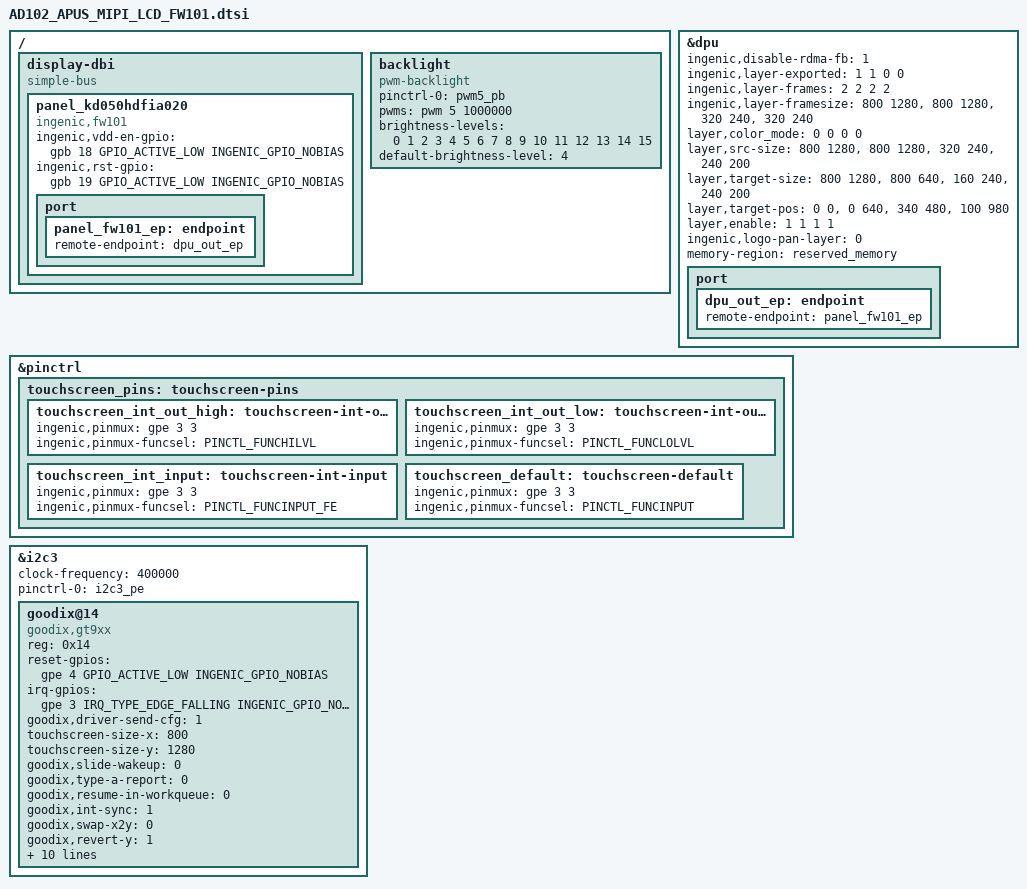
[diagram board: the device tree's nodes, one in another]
&dpu {
	status = "okay";
	ingenic,disable-rdma-fb = <1>;
	/*Defines the init state of composer fb export infomations.*/
	ingenic,layer-exported = <1 1 0 0>;
	ingenic,layer-frames   = <2 2 2 2>;
	ingenic,layer-framesize = <800 1280>, <800 1280>, <320 240>, <320 240>;   /*Max framesize for each layer.*/
	layer,color_mode        = <0 0 0 0>;                                    /*src fmt,*/
	layer,src-size          = <800 1280>, <800 1280>, <320 240>, <240 200>; /*Layer src size should smaller than framesize*/
	layer,target-size       = <800 1280>, <800 640>, <160 240>, <240 200>;  /*Target Size should smaller than src_size.*/
	layer,target-pos        = <0 0>, <0 640>, <340 480>, <100 980>; /*target pos , the start point of the target panel.*/
	layer,enable            = <1 1 1 1>;                                    /*layer enabled or disabled.*/
	ingenic,logo-pan-layer  = <0>;                                          /*on which layer should init logo pan on.*/
	memory-region=<&reserved_memory>;
	port {
		dpu_out_ep: endpoint {
		    remote-endpoint = <&panel_fw101_ep>;
		};
	};
};

/ {
	display-dbi {
		compatible = "simple-bus";
		#interrupt-cells = <1>;
		#address-cells = <1>;
		#size-cells = <1>;
		ranges = <>;
		panel_kd050hdfia020 {
			compatible = "ingenic,fw101";
			status = "okay";
			pinctrl-names = "default";
			ingenic,vdd-en-gpio = <&gpb 18 GPIO_ACTIVE_LOW INGENIC_GPIO_NOBIAS>;
			ingenic,rst-gpio = <&gpb 19 GPIO_ACTIVE_LOW INGENIC_GPIO_NOBIAS>;
			/*ingenic,lcd-pwm-gpio = <&gpb 18 GPIO_ACTIVE_HIGH INGENIC_GPIO_NOBIAS>;*/
			port {
				panel_fw101_ep: endpoint {
					remote-endpoint = <&dpu_out_ep>;
				};
			};
		};
	};

	backlight {
		compatible = "pwm-backlight";
	        pinctrl-names = "default";
	        pinctrl-0 = <&pwm5_pb>;
		pwms = <&pwm 5 1000000>;
		brightness-levels = <0 1 2 3 4 5 6 7 8 9 10 11 12 13 14 15>;
		default-brightness-level = <4>;
	};

};

&pinctrl {
	touchscreen_pins:touchscreen-pins {
		touchscreen_int_out_high:touchscreen-int-out-high {
				 ingenic,pinmux = <&gpe 3 3>;
				 ingenic,pinmux-funcsel = <PINCTL_FUNCHILVL>;
		};
		touchscreen_int_out_low:touchscreen-int-out-low {
				ingenic,pinmux = <&gpe 3 3>;
				ingenic,pinmux-funcsel = <PINCTL_FUNCLOLVL>;
		};
		touchscreen_int_input:touchscreen-int-input {
			      ingenic,pinmux = <&gpe 3 3>;
			      ingenic,pinmux-funcsel = <PINCTL_FUNCINPUT_FE>;
		};
		touchscreen_default:touchscreen-default {
			    ingenic,pinmux = <&gpe 3 3>;
			    ingenic,pinmux-funcsel = <PINCTL_FUNCINPUT>;
		};
	};
};

&i2c3 {
	status = "okay";
	clock-frequency = <400000>;
	pinctrl-names = "default";
	pinctrl-0 = <&i2c3_pe>;

	goodix@14{
		compatible = "goodix,gt9xx"; /* do not modify */
		reg = <0x14>; /* do not modify */
		reset-gpios = <&gpe 4 GPIO_ACTIVE_LOW INGENIC_GPIO_NOBIAS>; /* RST pin */
		irq-gpios = <&gpe 3 IRQ_TYPE_EDGE_FALLING INGENIC_GPIO_NOBIAS>; /* INT pin */
		goodix,driver-send-cfg = <1>;
		touchscreen-size-x = <800>;
		touchscreen-size-y = <1280>;
		goodix,slide-wakeup = <0>;
		goodix,type-a-report = <0>;
		goodix,resume-in-workqueue = <0>;
		goodix,int-sync = <1>;
		goodix,swap-x2y = <0>;
		goodix,revert-y = <1>;
		goodix,auto-update-cfg = <0>;
		goodix,power-off-sleep = <0>;
		goodix,pen-suppress-finger = <0>;
		irq-flags = <2>; /* 1 rising, 2 falling */
		pinctrl-names = "default", "int-output-high", "int-output-low", "int-input";
		pinctrl-0 = <&touchscreen_default>;
		pinctrl-1 = <&touchscreen_int_out_high>;
		pinctrl-2 = <&touchscreen_int_out_low>;
		pinctrl-3 = <&touchscreen_int_input>;
		goodix,cfg-group0 = [
			6B 20 03 00 05 0A 35 00 01 0F 1E
                        0F 4B 32 03 05 00 00 00 00 00 00
                        04 18 1A 1E 14 90 30 AA BA BC EE
                        06 00 00 00 B9 03 11 00 00 00 00
                        00 00 00 00 00 00 00 78 DC 94 D5
                        02 0C 32 00 04 77 7F 00 73 90 00
                        71 A2 00 70 B7 00 70 CF 00 6F 00
                        00 00 00 00 00 00 00 00 00 00 00
                        00 00 00 00 00 00 00 00 00 00 00
                        00 00 00 00 00 00 00 00 00 00 00
                        00 00 19 18 17 16 15 14 11 10 0F
                        0E 0D 0C 09 08 07 06 05 04 01 00
                        00 00 00 00 00 00 00 00 00 00 2A
                        29 28 27 26 25 24 23 22 21 20 1F
                        1E 1C 1B 19 00 02 04 06 07 08 0A
                        0C 0D 0E 0F 10 11 12 13 14 00 00
                        00 00 00 00 00 00 00 00 A2 01];
	};
};
